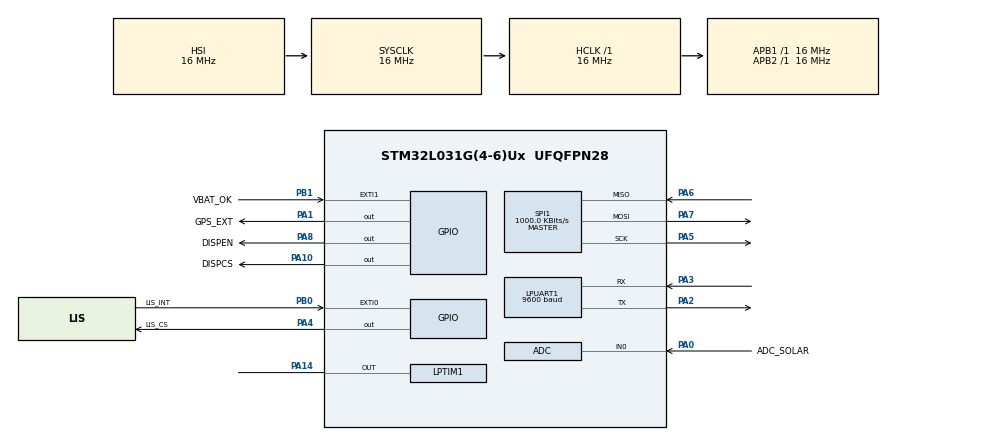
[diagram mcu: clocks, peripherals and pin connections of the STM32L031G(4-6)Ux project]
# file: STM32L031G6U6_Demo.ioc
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ADC.ClockPrescaler=ADC_CLOCK_ASYNC_DIV16
ADC.ContinuousConvMode=DISABLE
ADC.DMAContinuousRequests=DISABLE
ADC.DiscontinuousConvMode=DISABLE
ADC.EOCSelection=ADC_EOC_SINGLE_CONV
ADC.LowPowerAutoPowerOff=ENABLE
ADC.Overrun=ADC_OVR_DATA_OVERWRITTEN
ADC.OversamplingMode=DISABLE
ADC.SamplingTime=ADC_SAMPLETIME_12CYCLES_5
ADC.ScanConvMode=ADC_SCAN_DIRECTION_FORWARD
Dma.ADC.0.Direction=DMA_PERIPH_TO_MEMORY
Dma.ADC.0.Instance=DMA1_Channel1
Dma.ADC.0.MemDataAlignment=DMA_MDATAALIGN_HALFWORD
Dma.ADC.0.MemInc=DMA_MINC_ENABLE
Dma.ADC.0.Mode=DMA_NORMAL
Dma.ADC.0.PeriphDataAlignment=DMA_PDATAALIGN_HALFWORD
Dma.ADC.0.PeriphInc=DMA_PINC_DISABLE
Dma.ADC.0.Priority=DMA_PRIORITY_MEDIUM
Dma.Request0=ADC
Dma.Request1=SPI1_TX
Dma.SPI1_TX.1.Direction=DMA_MEMORY_TO_PERIPH
Dma.SPI1_TX.1.Instance=DMA1_Channel3
Dma.SPI1_TX.1.MemDataAlignment=DMA_MDATAALIGN_BYTE
Dma.SPI1_TX.1.MemInc=DMA_MINC_ENABLE
Dma.SPI1_TX.1.Mode=DMA_NORMAL
Dma.SPI1_TX.1.PeriphDataAlignment=DMA_PDATAALIGN_BYTE
Dma.SPI1_TX.1.PeriphInc=DMA_PINC_DISABLE
Dma.SPI1_TX.1.Priority=DMA_PRIORITY_LOW
LPTIM1.ClockPrescaler=LPTIM_PRESCALER_DIV1
LPUART1.BaudRate=9600
LPUART1.WordLength=UART_WORDLENGTH_8B
Mcu.Family=STM32L0
Mcu.Name=STM32L031G(4-6)Ux
Mcu.Package=UFQFPN28
NVIC.DMA1_Channel1_IRQn=true\:0\:0\:false\:false\:true\:false\:true\:true
NVIC.DMA1_Channel2_3_IRQn=true\:0\:0\:false\:false\:true\:false\:true\:true
NVIC.EXTI0_1_IRQn=true\:0\:0\:false\:false\:true\:true\:true\:true
NVIC.LPUART1_IRQn=true\:0\:0\:false\:false\:true\:true\:true\:true
PA0-CK_IN.GPIO_Label=ADC_SOLAR
PA0-CK_IN.Mode=IN0
PA0-CK_IN.Signal=ADC_IN0
PA1.GPIO_Label=GPS_EXT
PA1.Signal=GPIO_Output
PA10.GPIO_Label=DISPCS
PA10.Signal=GPIO_Output
PA14.Mode=WaveformGeneration
PA14.Signal=LPTIM1_OUT
PA2.Mode=Asynchronous
PA2.Signal=LPUART1_TX
PA3.Mode=Asynchronous
PA3.Signal=LPUART1_RX
PA4.GPIO_Label=LIS_CS
PA4.Signal=GPIO_Output
PA5.Mode=Full_Duplex_Master
PA5.Signal=SPI1_SCK
PA6.Mode=Full_Duplex_Master
PA6.Signal=SPI1_MISO
PA7.Mode=Full_Duplex_Master
PA7.Signal=SPI1_MOSI
PA8.GPIO_Label=DISPEN
PA8.Signal=GPIO_Output
PB0.GPIO_Label=LIS_INT
PB0.Signal=GPXTI0
PB1.GPIO_Label=VBAT_OK
PB1.GPIO_ModeDefaultEXTI=GPIO_MODE_IT_RISING_FALLING
PB1.Signal=GPXTI1
PC14-OSC32_IN.Mode=LSE-External-Oscillator
PC14-OSC32_IN.Signal=RCC_OSC32_IN
PC15-OSC32_OUT.Mode=LSE-External-Oscillator
PC15-OSC32_OUT.Signal=RCC_OSC32_OUT
ProjectManager.HeapSize=0x200
ProjectManager.StackSize=0x400
ProjectManager.TargetToolchain=STM32CubeIDE
RCC.AHBFreq_Value=16000000
RCC.APB1Freq_Value=16000000
RCC.APB1TimFreq_Value=16000000
RCC.APB2Freq_Value=16000000
RCC.APB2TimFreq_Value=16000000
RCC.HCLKFreq_Value=16000000
RCC.HSE_VALUE=8000000
RCC.HSI16_VALUE=16000000
RCC.HSI_VALUE=16000000
RCC.LSE_Drive_Capability=RCC_LSEDRIVE_MEDIUMLOW
RCC.LptimClockSelection=RCC_LPTIM1CLKSOURCE_LSE
RCC.Lpuart1ClockSelection=RCC_LPUART1CLKSOURCE_LSE
RCC.MSI_VALUE=2097000
RCC.PWR_Regulator_Voltage_Scale=PWR_REGULATOR_VOLTAGE_SCALE2
RCC.RTCClockSelection=RCC_RTCCLKSOURCE_LSE
RCC.RTCClockSelectionVirtual=RCC_RTCCLKSOURCE_LSE
RCC.SYSCLKFreq_VALUE=16000000
RCC.SYSCLKSource=RCC_SYSCLKSOURCE_HSI
RCC.VCOOutputFreq_Value=48000000
RCC.VDD_VALUE=3
RTC.WakeUpCounter-WakeUp=2048
SPI1.BaudRatePrescaler=SPI_BAUDRATEPRESCALER_16
SPI1.CalculateBaudRate=1000.0 KBits/s
SPI1.Direction=SPI_DIRECTION_2LINES
SPI1.Mode=SPI_MODE_MASTER
SPI1.VirtualType=VM_MASTER
VP_ADC_TempSens_Input.Mode=IN-TempSens
VP_ADC_Vref_Input.Mode=IN-Vrefint
VP_LPTIM1_VS_LPTIM_counterModeInternalClock.Mode=Counts__internal_clock_event_00
VP_RTC_VS_RTC_Activate.Mode=RTC_Enabled
VP_RTC_VS_RTC_WakeUp_intern.Mode=WakeUp
board=custom

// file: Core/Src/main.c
/* USER CODE BEGIN Header */
/**
 ******************************************************************************
 * @file           : main.c
 * @brief          : Main program body
 ******************************************************************************
 * @attention
 *
 * Copyright (c) 2022 STMicroelectronics.
 * All rights reserved.
 *
 * This software is licensed under terms that can be found in the LICENSE file
 * in the root directory of this software component.
 * If no LICENSE file comes with this software, it is provided AS-IS.
 *
 ******************************************************************************
 */
/* USER CODE END Header */
#include "main.h"

/* USER CODE BEGIN Includes */
#include "LS013B7DH03.h"

/* USER CODE END Includes */

ADC_HandleTypeDef hadc;
DMA_HandleTypeDef hdma_adc;

LPTIM_HandleTypeDef hlptim1;

RTC_HandleTypeDef hrtc;

SPI_HandleTypeDef hspi1;
DMA_HandleTypeDef hdma_spi1_tx;

void SystemClock_Config(void);
static void MX_GPIO_Init(void);
static void MX_ADC_Init(void);
static void MX_DMA_Init(void);
static void MX_LPTIM1_Init(void);
static void MX_LPUART1_UART_Init(void);
static void MX_RTC_Init(void);
static void MX_SPI1_Init(void);
/* USER CODE BEGIN PFP */

#ifdef __GNUC__
#define PUTCHAR_PROTOTYPE int __io_putchar(int ch)
#else
#define PUTCHAR_PROTOTYPE int fputc(int ch, FILE *f)
#endif

PUTCHAR_PROTOTYPE {
	lcd_writeChar((uint8_t*) &ch);
	return ch;
}

/* USER CODE END PFP */

int main(void)
{

  /* MCU Configuration--------------------------------------------------------*/

  /* Reset of all peripherals, Initializes the Flash interface and the Systick. */
  HAL_Init();

  /* Configure the system clock */
  SystemClock_Config();

  /* Initialize all configured peripherals */
  MX_GPIO_Init();
  MX_ADC_Init();
  MX_DMA_Init();
  MX_LPTIM1_Init();
  MX_LPUART1_UART_Init();
  MX_RTC_Init();
  MX_SPI1_Init();

  /* Infinite loop */
	while (1) {

	}
}

void SystemClock_Config(void)
{
  RCC_OscInitTypeDef RCC_OscInitStruct = {0};
  RCC_ClkInitTypeDef RCC_ClkInitStruct = {0};
  RCC_PeriphCLKInitTypeDef PeriphClkInit = {0};

  /** Configure the main internal regulator output voltage
  */
  __HAL_PWR_VOLTAGESCALING_CONFIG(PWR_REGULATOR_VOLTAGE_SCALE2);

  /** Configure LSE Drive Capability
  */
  HAL_PWR_EnableBkUpAccess();
  __HAL_RCC_LSEDRIVE_CONFIG(RCC_LSEDRIVE_MEDIUMLOW);

  /** Initializes the RCC Oscillators according to the specified parameters
  * in the RCC_OscInitTypeDef structure.
  */
  RCC_OscInitStruct.OscillatorType = RCC_OSCILLATORTYPE_HSI|RCC_OSCILLATORTYPE_LSE;
  RCC_OscInitStruct.LSEState = RCC_LSE_ON;
  RCC_OscInitStruct.HSIState = RCC_HSI_ON;
  RCC_OscInitStruct.HSICalibrationValue = RCC_HSICALIBRATION_DEFAULT;
  RCC_OscInitStruct.PLL.PLLState = RCC_PLL_NONE;
  if (HAL_RCC_OscConfig(&RCC_OscInitStruct) != HAL_OK)
  {
    Error_Handler();
  }

  /** Initializes the CPU, AHB and APB buses clocks
  */
  RCC_ClkInitStruct.ClockType = RCC_CLOCKTYPE_HCLK|RCC_CLOCKTYPE_SYSCLK
                              |RCC_CLOCKTYPE_PCLK1|RCC_CLOCKTYPE_PCLK2;
  RCC_ClkInitStruct.SYSCLKSource = RCC_SYSCLKSOURCE_HSI;
  RCC_ClkInitStruct.AHBCLKDivider = RCC_SYSCLK_DIV1;
  RCC_ClkInitStruct.APB1CLKDivider = RCC_HCLK_DIV1;
  RCC_ClkInitStruct.APB2CLKDivider = RCC_HCLK_DIV1;

  if (HAL_RCC_ClockConfig(&RCC_ClkInitStruct, FLASH_LATENCY_1) != HAL_OK)
  {
    Error_Handler();
  }
  PeriphClkInit.PeriphClockSelection = RCC_PERIPHCLK_LPUART1|RCC_PERIPHCLK_RTC
                              |RCC_PERIPHCLK_LPTIM1;
  PeriphClkInit.Lpuart1ClockSelection = RCC_LPUART1CLKSOURCE_LSE;
  PeriphClkInit.RTCClockSelection = RCC_RTCCLKSOURCE_LSE;
  PeriphClkInit.LptimClockSelection = RCC_LPTIM1CLKSOURCE_LSE;

  if (HAL_RCCEx_PeriphCLKConfig(&PeriphClkInit) != HAL_OK)
  {
    Error_Handler();
  }
}

static void MX_ADC_Init(void)
{

  ADC_ChannelConfTypeDef sConfig = {0};

  /** Configure the global features of the ADC (Clock, Resolution, Data Alignment and number of conversion)
  */
  hadc.Instance = ADC1;
  hadc.Init.OversamplingMode = DISABLE;
  hadc.Init.ClockPrescaler = ADC_CLOCK_ASYNC_DIV16;
  hadc.Init.Resolution = ADC_RESOLUTION_12B;
  hadc.Init.SamplingTime = ADC_SAMPLETIME_12CYCLES_5;
  hadc.Init.ScanConvMode = ADC_SCAN_DIRECTION_FORWARD;
  hadc.Init.DataAlign = ADC_DATAALIGN_RIGHT;
  hadc.Init.ContinuousConvMode = DISABLE;
  hadc.Init.DiscontinuousConvMode = DISABLE;
  hadc.Init.ExternalTrigConvEdge = ADC_EXTERNALTRIGCONVEDGE_NONE;
  hadc.Init.ExternalTrigConv = ADC_SOFTWARE_START;
  hadc.Init.DMAContinuousRequests = DISABLE;
  hadc.Init.EOCSelection = ADC_EOC_SINGLE_CONV;
  hadc.Init.Overrun = ADC_OVR_DATA_OVERWRITTEN;
  hadc.Init.LowPowerAutoWait = DISABLE;
  hadc.Init.LowPowerFrequencyMode = ENABLE;
  hadc.Init.LowPowerAutoPowerOff = ENABLE;
  if (HAL_ADC_Init(&hadc) != HAL_OK)
  {
    Error_Handler();
  }

  /** Configure for the selected ADC regular channel to be converted.
  */
  sConfig.Channel = ADC_CHANNEL_0;
  sConfig.Rank = ADC_RANK_CHANNEL_NUMBER;
  if (HAL_ADC_ConfigChannel(&hadc, &sConfig) != HAL_OK)
  {
    Error_Handler();
  }

  /** Configure for the selected ADC regular channel to be converted.
  */
  sConfig.Channel = ADC_CHANNEL_TEMPSENSOR;
  if (HAL_ADC_ConfigChannel(&hadc, &sConfig) != HAL_OK)
  {
    Error_Handler();
  }

  /** Configure for the selected ADC regular channel to be converted.
  */
  sConfig.Channel = ADC_CHANNEL_VREFINT;
  if (HAL_ADC_ConfigChannel(&hadc, &sConfig) != HAL_OK)
  {
    Error_Handler();
  }

}

static void MX_LPTIM1_Init(void)
{

  hlptim1.Instance = LPTIM1;
  hlptim1.Init.Clock.Source = LPTIM_CLOCKSOURCE_APBCLOCK_LPOSC;
  hlptim1.Init.Clock.Prescaler = LPTIM_PRESCALER_DIV1;
  hlptim1.Init.Trigger.Source = LPTIM_TRIGSOURCE_SOFTWARE;
  hlptim1.Init.OutputPolarity = LPTIM_OUTPUTPOLARITY_HIGH;
  hlptim1.Init.UpdateMode = LPTIM_UPDATE_IMMEDIATE;
  hlptim1.Init.CounterSource = LPTIM_COUNTERSOURCE_INTERNAL;
  if (HAL_LPTIM_Init(&hlptim1) != HAL_OK)
  {
    Error_Handler();
  }

}

static void MX_LPUART1_UART_Init(void)
{

  LL_LPUART_InitTypeDef LPUART_InitStruct = {0};

  LL_GPIO_InitTypeDef GPIO_InitStruct = {0};

  /* Peripheral clock enable */
  LL_APB1_GRP1_EnableClock(LL_APB1_GRP1_PERIPH_LPUART1);

  LL_IOP_GRP1_EnableClock(LL_IOP_GRP1_PERIPH_GPIOA);
  /**LPUART1 GPIO Configuration
  PA2   ------> LPUART1_TX
  PA3   ------> LPUART1_RX
  */
  GPIO_InitStruct.Pin = LL_GPIO_PIN_2;
  GPIO_InitStruct.Mode = LL_GPIO_MODE_ALTERNATE;
  GPIO_InitStruct.Speed = LL_GPIO_SPEED_FREQ_VERY_HIGH;
  GPIO_InitStruct.OutputType = LL_GPIO_OUTPUT_PUSHPULL;
  GPIO_InitStruct.Pull = LL_GPIO_PULL_NO;
  GPIO_InitStruct.Alternate = LL_GPIO_AF_6;
  LL_GPIO_Init(GPIOA, &GPIO_InitStruct);

  GPIO_InitStruct.Pin = LL_GPIO_PIN_3;
  GPIO_InitStruct.Mode = LL_GPIO_MODE_ALTERNATE;
  GPIO_InitStruct.Speed = LL_GPIO_SPEED_FREQ_VERY_HIGH;
  GPIO_InitStruct.OutputType = LL_GPIO_OUTPUT_PUSHPULL;
  GPIO_InitStruct.Pull = LL_GPIO_PULL_NO;
  GPIO_InitStruct.Alternate = LL_GPIO_AF_6;
  LL_GPIO_Init(GPIOA, &GPIO_InitStruct);

  /* LPUART1 interrupt Init */
  NVIC_SetPriority(LPUART1_IRQn, 0);
  NVIC_EnableIRQ(LPUART1_IRQn);

  LPUART_InitStruct.BaudRate = 9600;
  LPUART_InitStruct.DataWidth = LL_LPUART_DATAWIDTH_8B;
  LPUART_InitStruct.StopBits = LL_LPUART_STOPBITS_1;
  LPUART_InitStruct.Parity = LL_LPUART_PARITY_NONE;
  LPUART_InitStruct.TransferDirection = LL_LPUART_DIRECTION_TX_RX;
  LPUART_InitStruct.HardwareFlowControl = LL_LPUART_HWCONTROL_NONE;
  LL_LPUART_Init(LPUART1, &LPUART_InitStruct);

}

static void MX_RTC_Init(void)
{

  /** Initialize RTC Only
  */
  hrtc.Instance = RTC;
  hrtc.Init.HourFormat = RTC_HOURFORMAT_24;
  hrtc.Init.AsynchPrediv = 127;
  hrtc.Init.SynchPrediv = 255;
  hrtc.Init.OutPut = RTC_OUTPUT_DISABLE;
  hrtc.Init.OutPutRemap = RTC_OUTPUT_REMAP_NONE;
  hrtc.Init.OutPutPolarity = RTC_OUTPUT_POLARITY_HIGH;
  hrtc.Init.OutPutType = RTC_OUTPUT_TYPE_OPENDRAIN;
  if (HAL_RTC_Init(&hrtc) != HAL_OK)
  {
    Error_Handler();
  }

  /** Enable the WakeUp
  */
  if (HAL_RTCEx_SetWakeUpTimer(&hrtc, 2048, RTC_WAKEUPCLOCK_RTCCLK_DIV16) != HAL_OK)
  {
    Error_Handler();
  }

}

static void MX_SPI1_Init(void)
{

  /* SPI1 parameter configuration*/
  hspi1.Instance = SPI1;
  hspi1.Init.Mode = SPI_MODE_MASTER;
  hspi1.Init.Direction = SPI_DIRECTION_2LINES;
  hspi1.Init.DataSize = SPI_DATASIZE_8BIT;
  hspi1.Init.CLKPolarity = SPI_POLARITY_LOW;
  hspi1.Init.CLKPhase = SPI_PHASE_1EDGE;
  hspi1.Init.NSS = SPI_NSS_SOFT;
  hspi1.Init.BaudRatePrescaler = SPI_BAUDRATEPRESCALER_16;
  hspi1.Init.FirstBit = SPI_FIRSTBIT_MSB;
  hspi1.Init.TIMode = SPI_TIMODE_DISABLE;
  hspi1.Init.CRCCalculation = SPI_CRCCALCULATION_DISABLE;
  hspi1.Init.CRCPolynomial = 7;
  if (HAL_SPI_Init(&hspi1) != HAL_OK)
  {
    Error_Handler();
  }

}

static void MX_DMA_Init(void)
{

  /* DMA controller clock enable */
  __HAL_RCC_DMA1_CLK_ENABLE();

  /* DMA interrupt init */
  /* DMA1_Channel1_IRQn interrupt configuration */
  HAL_NVIC_SetPriority(DMA1_Channel1_IRQn, 0, 0);
  HAL_NVIC_EnableIRQ(DMA1_Channel1_IRQn);
  /* DMA1_Channel2_3_IRQn interrupt configuration */
  HAL_NVIC_SetPriority(DMA1_Channel2_3_IRQn, 0, 0);
  HAL_NVIC_EnableIRQ(DMA1_Channel2_3_IRQn);

}

static void MX_GPIO_Init(void)
{
  GPIO_InitTypeDef GPIO_InitStruct = {0};

  /* GPIO Ports Clock Enable */
  __HAL_RCC_GPIOC_CLK_ENABLE();
  __HAL_RCC_GPIOA_CLK_ENABLE();
  __HAL_RCC_GPIOB_CLK_ENABLE();

  /*Configure GPIO pin Output Level */
  HAL_GPIO_WritePin(GPIOA, GPS_EXT_Pin|LIS_CS_Pin|DISPEN_Pin|DISPCS_Pin, GPIO_PIN_RESET);

  /*Configure GPIO pins : GPS_EXT_Pin LIS_CS_Pin DISPEN_Pin DISPCS_Pin */
  GPIO_InitStruct.Pin = GPS_EXT_Pin|LIS_CS_Pin|DISPEN_Pin|DISPCS_Pin;
  GPIO_InitStruct.Mode = GPIO_MODE_OUTPUT_PP;
  GPIO_InitStruct.Pull = GPIO_NOPULL;
  GPIO_InitStruct.Speed = GPIO_SPEED_FREQ_LOW;
  HAL_GPIO_Init(GPIOA, &GPIO_InitStruct);

  /*Configure GPIO pin : LIS_INT_Pin */
  GPIO_InitStruct.Pin = LIS_INT_Pin;
  GPIO_InitStruct.Mode = GPIO_MODE_IT_RISING;
  GPIO_InitStruct.Pull = GPIO_NOPULL;
  HAL_GPIO_Init(LIS_INT_GPIO_Port, &GPIO_InitStruct);

  /*Configure GPIO pin : VBAT_OK_Pin */
  GPIO_InitStruct.Pin = VBAT_OK_Pin;
  GPIO_InitStruct.Mode = GPIO_MODE_IT_RISING_FALLING;
  GPIO_InitStruct.Pull = GPIO_NOPULL;
  HAL_GPIO_Init(VBAT_OK_GPIO_Port, &GPIO_InitStruct);

  /*Configure GPIO pins : PA9 PA13 PA15 */
  GPIO_InitStruct.Pin = GPIO_PIN_9|GPIO_PIN_13|GPIO_PIN_15;
  GPIO_InitStruct.Mode = GPIO_MODE_ANALOG;
  GPIO_InitStruct.Pull = GPIO_NOPULL;
  HAL_GPIO_Init(GPIOA, &GPIO_InitStruct);

  /*Configure GPIO pins : PB3 PB6 PB7 */
  GPIO_InitStruct.Pin = GPIO_PIN_3|GPIO_PIN_6|GPIO_PIN_7;
  GPIO_InitStruct.Mode = GPIO_MODE_ANALOG;
  GPIO_InitStruct.Pull = GPIO_NOPULL;
  HAL_GPIO_Init(GPIOB, &GPIO_InitStruct);

  /* EXTI interrupt init*/
  HAL_NVIC_SetPriority(EXTI0_1_IRQn, 0, 0);
  HAL_NVIC_EnableIRQ(EXTI0_1_IRQn);

}

void Error_Handler(void)
{
	__disable_irq();
	while (1) {
	}
}
